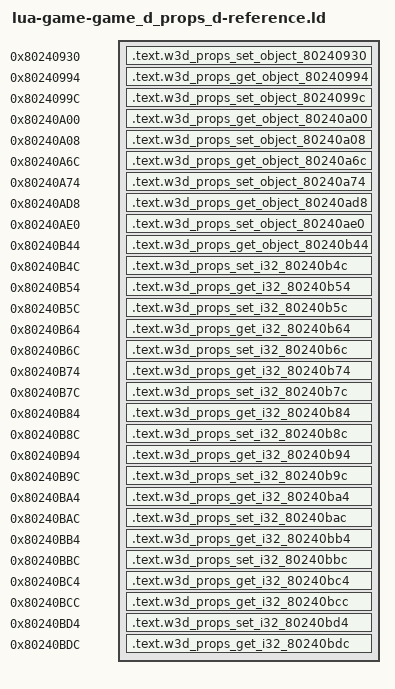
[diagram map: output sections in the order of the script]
/* Generated reference-only placements. All bodies are source-built. */
OUTPUT_FORMAT("elf32-powerpc")
OUTPUT_ARCH(powerpc)
ENTRY(w3d_props_set_object_80240930)
_SDA_BASE_ = 0x804b2540;
_SDA2_BASE_ = 0x804c2540;
SECTIONS {
  .text.w3d_props_set_object_80240930 0x80240930 : { *(.text.w3d_props_set_object_80240930) }
  .text.w3d_props_get_object_80240994 0x80240994 : { *(.text.w3d_props_get_object_80240994) }
  .text.w3d_props_set_object_8024099c 0x8024099c : { *(.text.w3d_props_set_object_8024099c) }
  .text.w3d_props_get_object_80240a00 0x80240a00 : { *(.text.w3d_props_get_object_80240a00) }
  .text.w3d_props_set_object_80240a08 0x80240a08 : { *(.text.w3d_props_set_object_80240a08) }
  .text.w3d_props_get_object_80240a6c 0x80240a6c : { *(.text.w3d_props_get_object_80240a6c) }
  .text.w3d_props_set_object_80240a74 0x80240a74 : { *(.text.w3d_props_set_object_80240a74) }
  .text.w3d_props_get_object_80240ad8 0x80240ad8 : { *(.text.w3d_props_get_object_80240ad8) }
  .text.w3d_props_set_object_80240ae0 0x80240ae0 : { *(.text.w3d_props_set_object_80240ae0) }
  .text.w3d_props_get_object_80240b44 0x80240b44 : { *(.text.w3d_props_get_object_80240b44) }
  .text.w3d_props_set_i32_80240b4c 0x80240b4c : { *(.text.w3d_props_set_i32_80240b4c) }
  .text.w3d_props_get_i32_80240b54 0x80240b54 : { *(.text.w3d_props_get_i32_80240b54) }
  .text.w3d_props_set_i32_80240b5c 0x80240b5c : { *(.text.w3d_props_set_i32_80240b5c) }
  .text.w3d_props_get_i32_80240b64 0x80240b64 : { *(.text.w3d_props_get_i32_80240b64) }
  .text.w3d_props_set_i32_80240b6c 0x80240b6c : { *(.text.w3d_props_set_i32_80240b6c) }
  .text.w3d_props_get_i32_80240b74 0x80240b74 : { *(.text.w3d_props_get_i32_80240b74) }
  .text.w3d_props_set_i32_80240b7c 0x80240b7c : { *(.text.w3d_props_set_i32_80240b7c) }
  .text.w3d_props_get_i32_80240b84 0x80240b84 : { *(.text.w3d_props_get_i32_80240b84) }
  .text.w3d_props_set_i32_80240b8c 0x80240b8c : { *(.text.w3d_props_set_i32_80240b8c) }
  .text.w3d_props_get_i32_80240b94 0x80240b94 : { *(.text.w3d_props_get_i32_80240b94) }
  .text.w3d_props_set_i32_80240b9c 0x80240b9c : { *(.text.w3d_props_set_i32_80240b9c) }
  .text.w3d_props_get_i32_80240ba4 0x80240ba4 : { *(.text.w3d_props_get_i32_80240ba4) }
  .text.w3d_props_set_i32_80240bac 0x80240bac : { *(.text.w3d_props_set_i32_80240bac) }
  .text.w3d_props_get_i32_80240bb4 0x80240bb4 : { *(.text.w3d_props_get_i32_80240bb4) }
  .text.w3d_props_set_i32_80240bbc 0x80240bbc : { *(.text.w3d_props_set_i32_80240bbc) }
  .text.w3d_props_get_i32_80240bc4 0x80240bc4 : { *(.text.w3d_props_get_i32_80240bc4) }
  .text.w3d_props_get_i32_80240bcc 0x80240bcc : { *(.text.w3d_props_get_i32_80240bcc) }
  .text.w3d_props_set_i32_80240bd4 0x80240bd4 : { *(.text.w3d_props_set_i32_80240bd4) }
  .text.w3d_props_get_i32_80240bdc 0x80240bdc : { *(.text.w3d_props_get_i32_80240bdc) }
  /DISCARD/ : { *(.text*) *(.rodata*) *(.data*) *(.bss*) *(.sdata*) *(.sbss*) *(.comment) }
}
